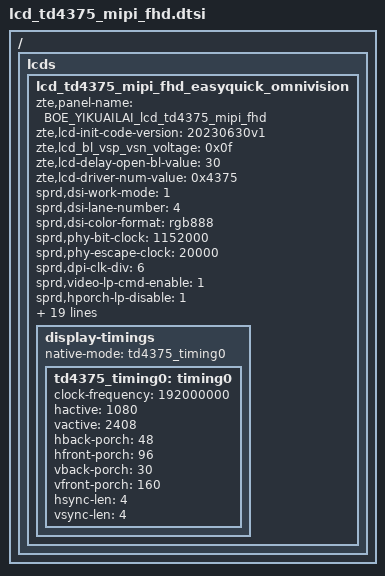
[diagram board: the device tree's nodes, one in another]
// SPDX-License-Identifier: GPL-2.0-only
/*
 * Unisoc ili9881c Truly LCD config DTS file
 *
 * Copyright (C) 2021, Unisoc Inc.
 */
/ {
	fragment {
		target-path = "/";
		__overlay__ {
			lcds {
				lcd_td4375_mipi_fhd_easyquick_omnivision: lcd_td4375_mipi_fhd_easyquick_omnivision {
					zte,panel-name = "BOE_YIKUAILAI_lcd_td4375_mipi_fhd";
					zte,lcd-init-code-version = "20230630v1";
					zte,lcd_bl_vsp_vsn_voltage = <0x0f>;
					zte,lcd-delay-open-bl-value = <30>;
					zte,lcd-driver-num-value = <0x4375>;
					sprd,dsi-work-mode = <1>;
					sprd,dsi-lane-number = <4>;
					sprd,dsi-color-format = "rgb888";

					sprd,phy-bit-clock = <1152000>;	/* kbps */
					sprd,phy-escape-clock = <20000>;/* kHz */

					sprd,dpi-clk-div = <6>;
					sprd,video-lp-cmd-enable = <1>;
					sprd,hporch-lp-disable = <1>;
					sprd,width-mm = <68430>;/*zte mod for 6.58*/
					sprd,height-mm = <152570>;/*zte mod for 6.58*/
					lcd-glass = "BOE";
					lcd-module = "YIKUAILAI";
					lcd-name = "TD4375";

					sprd,esd-check-enable = <1>;/* 0:close , 1:open */
					sprd,esd-check-mode = <0>;/* 0:REG ,1:TE  */
					sprd,esd-check-period = <1000>;
					sprd,esd-check-register = <0x0A>;
					sprd,esd-check-value = <0x1C>;

					sprd,reset-on-sequence = <1 10>, <0 10>, <1 50>;
					sprd,reset-off-sequence = <0 20>;
					zte,tp-resetpin-suspend-keep-low;

					//sprd,use-dcs-write;
					sprd,initial-command = [
29 00 00 02 B0 00
29 00 00 0B B6 30 6B 00 86 03 0A 13 1A 00 00
29 00 00 05 B7 51 00 00 00
29 00 00 08 B8 57 3D 19 BE 1E 0A 0A
29 00 00 08 B9 6F 3D 28 BE 3C 14 0A
29 00 00 08 BA 33 57 00 00 00 00 0A
29 00 00 0C BB 44 26 C3 1F 19 06 03 C0 00 00 10
29 00 00 0C BC 32 4C C3 52 32 1F 03 F2 00 00 13
29 00 00 0C BD 24 68 C3 AA 3F 32 03 FF 00 00 25
29 00 00 0D BE 00 00 00 00 00 00 00 00 00 00 00 00
29 00 00 18 C0 00 C4 01 2C 0A 09 68 00 82 22 00 08 00 70 00 00 00 00 00 00 00 00 02
29 00 00 35 C1 30 00 00 11 00 00 00 00 22 00 05 20 00 80 FA 40 00 84 0F 00 00 00 00 00 00 00 00 00 00 00 00 00 00 00 00 00 00 00 00 00 00 01 2C 08 08 00 0A 28 0F 3C 14 50
29 00 00 8E C2 00 30 C7 02 02 10 03 05 00 00 00 00 00 00 00 00 00 00 00 00 00 00 00 00 00 00 00 00 60 BD 04 04 01 01 C1 00 A0 0A 00 00 02 08 00 00 00 00 11 00 A0 0A 04 00 00 00 00 00 00 00 00 00 00 00 00 00 00 00 00 00 00 00 00 00 11 00 00 00 00 00 00 00 00 00 00 00 00 00 00 00 00 00 00 00 00 00 00 00 11 00 00 00 00 00 00 00 00 00 00 00 00 00 00 00 00 00 00 00 00 00 00 00 11 00 00 00 00 00 00 00 00 00 00 00 00 00 00 00 00 00 00 00 00
29 00 00 6D C3 00 00 C1 01 97 C9 A2 00 00 00 00 00 CE 01 00 0A 01 00 00 00 00 00 00 00 00 00 00 00 00 00 00 00 00 00 00 00 00 00 00 00 00 00 00 00 00 00 00 00 00 00 00 00 00 00 00 00 00 00 00 00 00 00 00 AA AA 00 00 00 00 00 00 0A 00 00 00 00 02 00 00 C0 00 0A 00 D0 00 00 01 00 00 C0 00 0A 00 D0 00 00 01 00 00 C0 00 00 00 00 00 00 00 00
29 00 00 6E C4 00 00 45 45 4d 4d 61 5f 5d 61 5f 5d 53 0f 0e 11 10 44 4f 4f be bf 03 02 00 00 45 45 4d 4d 61 5f 5d 61 5f 5d 53 0f 0e 11 10 44 4f 4f be bf 03 02 ff ff ff ff ff ff F1 FF F3 F1 FF F3 00 00 0C 00 00 0C c0 0f 00 c0 0f c0 00 00 00 00 00 00 00 00 00 00 00 00 00 00 00 00 00 58 55 01 00 00 01 00 00 00 00 00 00 00 00 00 00 00 00 00 00
29 00 00 06 C5 08 00 00 00 00
29 00 00 3F C6 02 0A 08 FC FF FF FF 00 00 13 01 AF 00 01 07 3B 3B 3B 00 00 00 34 05 09 28 28 01 07 3B 3B 3B 01 0B 00 00 00 1E 01 00 00 00 00 00 00 20 20 00 00 12 00 00 00 00 00 22 22 00 00 00 00 10 00
29 00 00 0F CB 20 80 70 00 20 00 00 2D 41 00 00 00 00 FF
29 00 00 02 CD 00
29 00 00 24 CE 75 40 49 53 59 5E 63 68 6E 74 7E 8A 98 A8 BB D0 E7 FF 31 5F 00 00 45 00 69 5A 40 11 F4 00 00 04 FA 00 00
29 00 00 07 CF 00 00 80 46 61 00
29 00 00 13 D0 CC 14 D5 66 09 B0 00 CF EF E5 D4 0B 52 FE 09 09 CF 00
29 00 00 2C D1 D3 D3 1B B0 07 07 3B 11 31 33 31 05 33 7B 07 33 3B 78 D2 D2 06 96 13 93 22 22 22 B3 BB 80 00 BB BB 11 08 08 84 C0 09 77 FF 11 44
29 00 00 03 D2 00 00
29 00 00 18 D4 00 00 00 00 00 00 00 00 00 00 00 00 00 00 00 00 00 00 00 00 00 00 00
29 00 00 4B D7 21 10 52 52 00 C4 00 0C 00 C4 04 FD 01 00 03 03 05 05 00 03 04 05 00 04 03 08 02 08 06 03 08 04 08 10 0C 0B 0A 0A 0A 07 08 0A 06 00 08 00 04 05 09 00 04 04 04 04 04 04 04 00 04 04 04 04 04 04 04 04 04 04 06 06 05 05 05 00
29 00 00 3F D8 00 12 00 00 00 00 00 00 00 00 00 00 00 00 00 00 00 00 00 00 00 00 00 00 00 00 00 00 00 00 00 00 00 00 00 00 00 00 00 00 00 00 00 00 00 00 00 00 00 00 00 00 00 00 00 00 00 00 00 00 00 00
29 00 00 17 D9 40 97 26 ED 0E BA 16 6C 16 6C 00 30 00 14 00 14 00 0C 00 00 01 00
29 00 00 05 DD 30 06 23 65
29 00 00 0B DE 00 00 00 0F FF 00 00 00 00 10
29 00 00 0B E6 00 00 00 00 00 00 00 00 00 00
29 00 00 B7 E7 11 00 89 30 80 09 68 04 38 00 08 02 1C 02 1C 02 00 02 0E 20 00 BB 00 07 0C 0D B7 0C B7 18 00 10 F0 03 0C 20 00 06 0B 0B 33 0E 1C 2A 38 46 54 62 69 70 77 79 7B 7D 7E 01 02 01 00 09 40 09 BE 19 FC 19 FA 19 F8 1A 38 1A 78 1A B6 2A F6 2B 34 2B 74 3B 74 6B F4 00 00 00 00 00 00 00 00 00 00 00 00 00 00 00 00 00 00 00 00 00 00 00 00 00 00 00 00 00 00 00 00 00 00 00 00 00 00 00 00 10 20 00 06 0F 0F 33 0E 1C 2A 38 46 54 62 69 70 77 79 7B 7D 7E 01 C2 22 00 2A 40 2A BE 3A FC 3A FA 3A F8 3B 38 3B 78 3B 76 4B B6 4B B6 4B F4 63 F4 7C 34 00 00 00 00 00 00
29 00 00 05 E8 00 30 63 00
29 00 00 1F EA 01 0E 09 60 0A 80 00 00 09 00 01 B8 00 00 00 00 00 00 00 00 04 C2 00 12 00 C4 0C 40 86 00
29 00 00 08 EB 00 00 00 00 01 00 11
29 00 00 0B EC 05 F0 00 10 9F 0A 80 00 02 3A
29 00 00 21 ED 01 01 02 02 08 08 09 09 00 00 00 00 02 00 00 00 00 00 01 4A 00 00 00 50 00 01 4A 00 00 A0 10 00
29 00 00 61 EE 01 17 00 00 00 75 01 00 00 00 00 F2 43 5D C0 05 00 00 00 00 00 00 00 00 43 0D 70 01 10 09 09 09 09 00 00 00 00 00 00 08 01 00 00 00 00 00 00 00 00 00 00 00 00 00 00 17 00 00 00 00 00 00 00 00 00 00 00 00 00 00 00 00 00 00 00 00 00 00 00 00 00 00 00 00 00 00 00 00 00 00 00 00 00 00 00 00
29 00 00 54 EF 00 C0 47 08 20 00 00 00 00 35 35 35 00 00 00 00 00 00 00 00 00 00 C0 47 08 20 35 35 35 00 00 00 00 00 00 10 00 10 00 08 10 00 10 00 0A 06 40 00 00 00 00 4B 00 03 51 00 00 05 00 00 00 00 00 00 00 00 00 00 00 00 00 00 00 00 00 00 00 00 00 00 00 00 00
29 00 00 17 F1 00 00 00 00 00 00 00 00 00 00 00 00 00 00 00 00 00 00 00 00 00 00
29 00 00 09 F9 44 3F 00 8D BF 00 09 1D
29 00 00 02 B0 03
29 00 00 02 B0 04
29 00 00 05 E5 03 00 00 00
29 00 00 05 D5 00 28 00 28
29 00 00 4D C7 00 00 00 CA 01 3C 01 59 01 70 01 76 01 7D 01 78 01 8F 01 5D 01 AE 01 6A 01 AA 01 61 01 C4 01 B9 02 33 02 9D 02 AD 00 00 00 CA 01 3C 01 59 01 70 01 76 01 7D 01 78 01 8F 01 5D 01 AE 01 6A 01 AA 01 61 01 C4 01 B9 02 33 02 9D 02 AD
29 00 00 02 51 FF
29 00 00 02 53 0C
29 00 00 02 55 00
29 00 00 02 B0 03
05 50 00 01 11
05 0A 00 01 29
						];
					sprd,sleep-in-command = [
						05 0A 00 01 28
						05 50 00 01 10
						];
					sprd,sleep-out-command = [
						05 50 00 01 11
						05 0A 00 01 29
						];

					display-timings {
						native-mode = <&td4375_timing0>;

						td4375_timing0:timing0 {
							clock-frequency = <192000000>;
							hactive = <1080>;
							vactive = <2408>;
							hback-porch = <48>;
							hfront-porch = <96>;
							vback-porch = <30>;
							vfront-porch = <160>;
							hsync-len = <4>;
							vsync-len = <4>;
						};
					};
				};
			};
		};
	};
};
